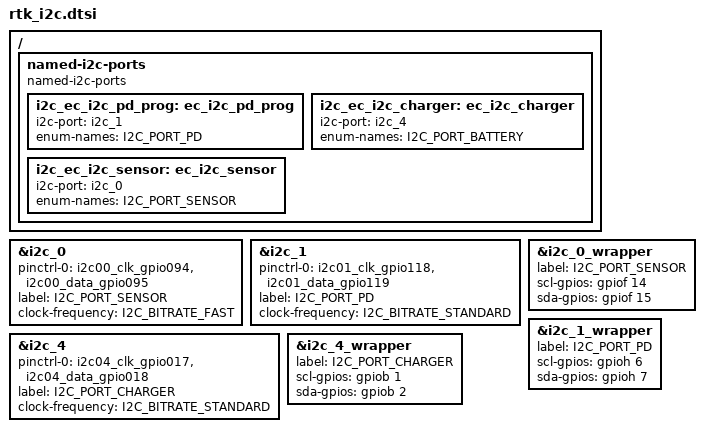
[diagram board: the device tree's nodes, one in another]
/* Copyright 2025 The ChromiumOS Authors
 * Use of this source code is governed by a BSD-style license that can be
 * found in the LICENSE file.
 */
/ {
	named-i2c-ports {
		compatible = "named-i2c-ports";

		i2c_ec_i2c_pd_prog: ec_i2c_pd_prog {
			i2c-port = <&i2c_1>;
			enum-names = "I2C_PORT_PD";
		};
		i2c_ec_i2c_charger: ec_i2c_charger {
			i2c-port = <&i2c_4>;
			enum-names = "I2C_PORT_BATTERY";
		};
		i2c_ec_i2c_sensor: ec_i2c_sensor {
			i2c-port = <&i2c_0>;
			enum-names = "I2C_PORT_SENSOR";
		};
	};
};

&i2c_0 {
	pinctrl-0 = <&i2c00_clk_gpio094
		     &i2c00_data_gpio095>;
	pinctrl-names = "default";

	label = "I2C_PORT_SENSOR";
	clock-frequency = <I2C_BITRATE_FAST>;
	status = "okay";
};

&i2c_1 {
	pinctrl-0 = <&i2c01_clk_gpio118
		     &i2c01_data_gpio119>;
	pinctrl-names = "default";

	label = "I2C_PORT_PD";
	clock-frequency = <I2C_BITRATE_STANDARD>;
	status = "okay";
};

&i2c_4 {
	pinctrl-0 = <&i2c04_clk_gpio017
		     &i2c04_data_gpio018>;
	pinctrl-names = "default";

	label = "I2C_PORT_CHARGER";
	clock-frequency = <I2C_BITRATE_STANDARD>;
	status = "okay";
};

&i2c_0_wrapper {
	label = "I2C_PORT_SENSOR";
	status = "okay";
	scl-gpios = <&gpiof 14 GPIO_ACTIVE_HIGH>;
	sda-gpios = <&gpiof 15 GPIO_ACTIVE_HIGH>;
};

&i2c_1_wrapper {
	label = "I2C_PORT_PD";
	status = "okay";
	scl-gpios = <&gpioh 6 GPIO_ACTIVE_HIGH>;
	sda-gpios = <&gpioh 7 GPIO_ACTIVE_HIGH>;
};

&i2c_4_wrapper {
	label = "I2C_PORT_CHARGER";
	status = "okay";
	scl-gpios = <&gpiob 1 GPIO_ACTIVE_HIGH>;
	sda-gpios = <&gpiob 2 GPIO_ACTIVE_HIGH>;
};
